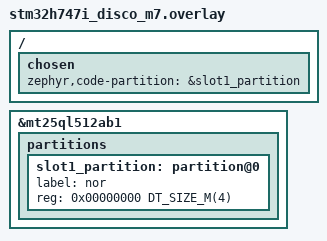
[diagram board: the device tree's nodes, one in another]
/*
 * Copyright (c) 2023 STMicroelectronics
 *
 * SPDX-License-Identifier: Apache-2.0
 */

/* mapp the slot1 partition in the external NOR */
/delete-node/ &slot1_partition;

/ {
	chosen {
		zephyr,code-partition = &slot1_partition;
	};
};

&mt25ql512ab1 {
		partitions {
			   /* put image at offset 0 in slot1 */
			   slot1_partition:partition@0 {
			       label = "nor";
			       reg = <0x00000000 DT_SIZE_M(4)>;
			   };
	};
};
